# NUC400_v1 register map
File version: 1.0
Registers are 32-bit, read-write, reset 0x0 unless marked. A register's access mark holds for its fields unless they carry their own. Offsets are from the block's base; [hi:lo] are bit positions; {n}, {i} and the like mark numbered series.

## SYS — SYS Register Map
Base 0x40000000
0x00 SYS_PDID ro reset 0x140018 — Part Device Identification Number Register
  [31:0] PDID — Part Device Identification Number. This register reflects device part number code. S/W can read this register to identify which device is used.
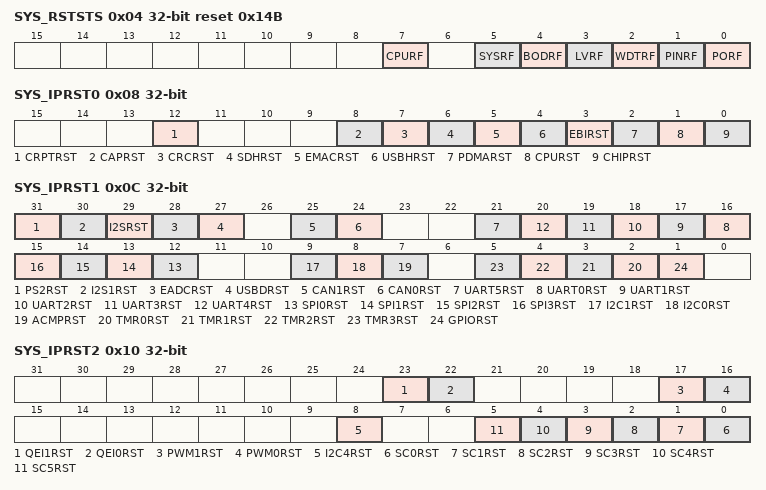
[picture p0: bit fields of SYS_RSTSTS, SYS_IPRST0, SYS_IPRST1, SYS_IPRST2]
0x04 SYS_RSTSTS reset 0x14B — System Reset Source Register
  [7] CPURF — CPU Reset Flag. The CPU reset flag is set by hardware if software writes CPURST (SYS_IPRST0[1]) 1 to reset Cortex-M4 Core and Flash Memory Controller (FMC). Note: Write to clear this bit to 0.
    0=No reset from CPU; 1=The Cortex-M4 Core and FMC are reset by software setting CPURST to 1
  [5] SYSRF — System Reset Flag. The system reset flag is set by the "Reset Signal" from the Cortex-M4 Core to indicate the previous reset source. Note: Write 1 to clear this bit to 0.
    0=No reset from Cortex-M4; 1=The Cortex-M4 had issued the reset signal to reset the system by writing 1 to the bit SYSRESETREQ(AIRCR[2], Application Interrupt and Reset Control Register, address = 0xE000ED0C) in system control registers of Cortex-M4 core
  [4] BODRF — BOD Reset Flag. The BOD reset flag is set by the "Reset Signal" from the Brown-Out Detector to indicate the previous reset source. Note: Write 1 to clear this bit to 0.
    0=No reset from BOD; 1=The BOD had issued the reset signal to reset the system
  [3] LVRF — LVR Reset Flag. The LVR reset flag is set by the "Reset Signal" from the Low Voltage Reset Controller to indicate the previous reset source. Note: Write 1 to clear this bit to 0.
    0=No reset from LVR; 1=LVR controller had issued the reset signal to reset the system
  [2] WDTRF — WDT Reset Flag. The WDT reset flag is set by the "Reset Signal" from the Watchdog Timer or Window Watchdog Timer to indicate the previous reset source. Note1: Write 1 to clear this bit to 0. Note2: Watchdog Timer register RSTF(WDT_CTL[2]) bit is set if the system has been reset by WDT time-out reset. Window Watchdog Timer register WWDTRF(WWDT_STATUS[1]) bit is set if the system has been reset by WWDT time-out reset.
    0=No reset from watchdog timer or window watchdog timer; 1=The watchdog timer or window watchdog timer had issued the reset signal to reset the system
  [1] PINRF — nRESET Pin Reset Flag. The nRESET pin reset flag is set by the "Reset Signal" from the nRESET Pin to indicate the previous reset source. Note: Write 1 to clear this bit to 0.
    0=No reset from nRESET pin; 1=Pin nRESET had issued the reset signal to reset the system
  [0] PORF — POR Reset Flag. The POR reset flag is set by the "Reset Signal" from the Power-on Reset (POR) Controller or bit CHIPRST (SYS_IPRST0[0]) to indicate the previous reset source. Note: Write 1 to clear this bit to 0.
    0=No reset from POR or CHIPRST; 1=Power-on Reset (POR) or CHIPRST had issued the reset signal to reset the system
0x08 SYS_IPRST0 — Peripheral Controller Reset Control Register 1
  [12] CRPTRST — CRYPTO Controller Reset (Write Protect). Setting this bit to 1 will generate a reset signal to the CRYPTO controller. User needs to set this bit to 0 to release from the reset state. This bit is a write protected bit, It means programming this bit needs to write "59h", "16h", "88h" to address 0x4000_0100 to disable register protection. Refer to the register SYS_REGLCTL at address GCR_BA+0x100
    0=CRYPTO controller normal operation; 1=CRYPTO controller reset
  [8] CAPRST — Image Capture Controller Reset (Write Protect). Setting this bit to 1 will generate a reset signal to the CAP controller. User needs to set this bit to 0 to release from the reset state. This bit is a write protected bit, It means programming this bit needs to write "59h", "16h", "88h" to address 0x4000_0100 to disable register protection. Reference the register SYS_REGLCTL at address GCR_BA+0x100
    0=CAP controller normal operation; 1=CAP controller reset
  [7] CRCRST — CRC Controller Reset (Write Protect). Setting this bit to 1 will generate a reset signal to the CRC controller. User needs to set this bit to 0 to release from the reset state. This bit is a write protected bit, It means programming this bit needs to write "59h", "16h", "88h" to address 0x4000_0100 to disable register protection. Reference the register SYS_REGLCTL at address GCR_BA+0x100
    0=CRC controller normal operation; 1=CRC controller reset
  [6] SDHRST — SD HOST Controller Reset (Write Protect). Setting this bit to 1 will generate a reset signal to the SD HOST controller. User needs to set this bit to 0 to release from the reset state. This bit is a write protected bit, It means programming this bit needs to write "59h", "16h", "88h" to address 0x4000_0100 to disable register protection. Refer to the register SYS_REGLCTL at address GCR_BA+0x100
    0=SD HOST controller normal operation; 1=SD HOST controller reset
  [5] EMACRST — EMAC Controller Reset (Write Protect). Setting this bit to 1 will generate a reset signal to the EMAC controller. User needs to set this bit to 0 to release from the reset state. This bit is the protected bit, It means programming this bit needs to write "59h", "16h", "88h" to address 0x4000_0100 to disable register protection. Refer to the register SYS_REGLCTL at address GCR_BA+0x100
    0=EMAC controller normal operation; 1=EMAC controller reset
  [4] USBHRST — USBH Controller Reset (Write Protect). Setting this bit to 1 will generate a reset signal to the HSB HOST controller. User needs to set this bit to 0 to release from the reset state. This bit is a write protected bit, It means programming this bit needs to write "59h", "16h", "88h" to address 0x4000_0100 to disable register protection. Refer to the register SYS_REGLCTL at address GCR_BA+0x100
    0=USBH controller normal operation; 1=USBH controller reset
  [3] EBIRST — EBI Controller Reset (Write Protect). Setting this bit to 1 will generate a reset signal to the EBI. User needs to set this bit to 0 to release from the reset state. This bit is a write protected bit, It means programming this bit needs to write "59h", "16h", "88h" to address 0x4000_0100 to disable register protection. Refer to the register SYS_REGLCTL at address GCR_BA+0x100
    0=EBI controller normal operation; 1=EBI controller reset
  [2] PDMARST — PDMA Controller Reset (Write Protect). Setting this bit to 1 will generate a reset signal to the PDMA. User needs to set this bit to 0 to release from reset state. This bit is a write protected bit, It means programming this bit needs to write "59h", "16h", "88h" to address 0x4000_0100 to disable register protection. Refer to the register SYS_REGLCTL at address GCR_BA+0x100.
    0=PDMA controller normal operation; 1=PDMA controller reset
  [1] CPURST — Processor Core One-Shot Reset (Write Protect). Setting this bit will only reset the processor core and Flash Memory Controller(FMC), and this bit will automatically return to 0 after the 2 clock cycles. This bit is a write protected bit, It means programming this bit needs to write "59h", "16h", "88h" to address 0x4000_0100 to disable register protection. Refer to the register SYS_REGLCTL at address GCR_BA+0x100
    0=Processor core normal operation; 1=Processor core one-shot reset
  [0] CHIPRST — Chip One-Shot Reset (Write Protect). Setting this bit will reset the whole chip, including Processor core and all peripherals, and this bit will automatically return to 0 after the 2 clock cycles. The CHIPRST is same as the POR reset, all the chip controllers is reset and the chip setting from flash are also reload. This bit is a write protected bit, which means programming this bit needs to write "59h", "16h", "88h" to address 0x4000_0100 to disable register protection. Refer to the register SYS_REGLCTL at address GCR_BA+0x100
    0=Chip normal operation; 1=Chip one shot reset
0x0C SYS_IPRST1 — Peripheral Controller Reset Control Register 2
  [31] PS2RST — PS/2 Controller Reset
    0=PS/2 controller normal operation; 1=PS/2 controller reset
  [30] I2S1RST — I2S1 Controller Reset
    0=I2S1 controller normal operation; 1=I2S1 controller reset
  [29] I2SRST — I2S Controller Reset
    0=I2S controller normal operation; 1=I2S controller reset
  [28] EADCRST — ADC Controller Reset
    0=ADC controller normal operation; 1=ADC controller reset
  [27] USBDRST — USB Device Controller Reset
    0=USB device controller normal operation; 1=USB device controller reset
  [25] CAN1RST — CAN1 Controller Reset
    0=CAN1 controller normal operation; 1=CAN1 controller reset
  [24] CAN0RST — CAN0 Controller Reset
    0=CAN0 controller normal operation; 1=CAN0 controller reset
  [21] UART5RST — UART2 Controller Reset
    0=UART5 controller normal operation; 1=UART5 controller reset
  [n+16] UART{n}RST (n=0..4) — UART{n} Controller Reset
    0=UART{n} controller normal operation; 1=UART{n} controller reset
  [n+12] SPI{n}RST (n=0..3) — SPI{n} Controller Reset
    0=SPI{n} controller normal operation; 1=SPI{n} controller reset
  [9] I2C1RST — I2C1 Controller Reset
    0=I2C1 controller normal operation; 1=I2C1 controller reset
  [8] I2C0RST — I2C0 Controller Reset
    0=I2C0 controller normal operation; 1=I2C0 controller reset
  [7] ACMPRST — Analog Comparator Controller Reset
    0=Analog Comparator controller normal operation; 1=Analog Comparator controller reset
  [n+2] TMR{n}RST (n=0..3) — Timer{n} Controller Reset
    0=Timer{n} controller normal operation; 1=Timer{n} controller reset
  [1] GPIORST — GPIO Controller Reset
    0=GPIO controller normal operation; 1=GPIO controller reset
0x10 SYS_IPRST2 — Peripheral Controller Reset Control Register 3
  [23] QEI1RST — QEI1 Controller Reset
    0=QEI1 controller normal operation; 1=QEI1 controller reset
  [22] QEI0RST — QEI0 Controller Reset
    0=QEI0 controller normal operation; 1=QEI0 controller reset
  [17] PWM1RST — PWM1 Controller Reset
    0=PWM1 controller normal operation; 1=PWM1 controller reset
  [16] PWM0RST — PWM0 Controller Reset
    0=PWM0 controller normal operation; 1=PWM0 controller reset
  [8] I2C4RST — I2C4 Controller Reset
    0=I2C4 controller normal operation; 1=I2C4 controller reset
  [n] SC{n}RST (n=0..5) — SC{n} Controller Reset
    0=SC{n} controller normal operation; 1=SC{n} controller reset
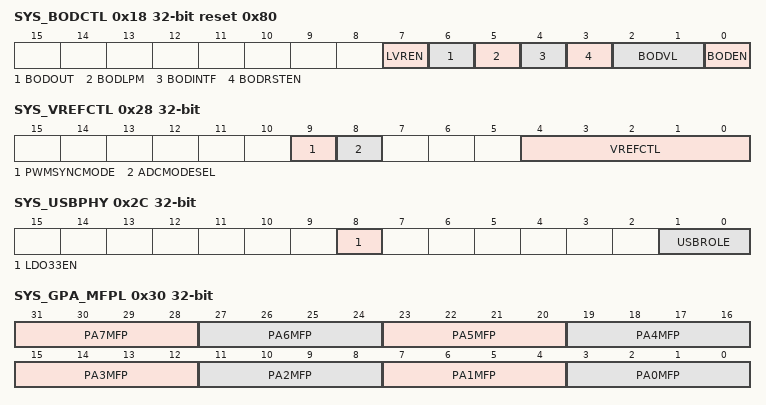
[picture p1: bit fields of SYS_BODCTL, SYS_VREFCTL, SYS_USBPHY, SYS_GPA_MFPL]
0x18 SYS_BODCTL reset 0x80 (reset mask 0xFFFFFFF0) — Brown-out Detector Control Register
  [7] LVREN — Low Voltage Reset Enable Bit (Write Protect). The LVR function reset the chip when the input power voltage is lower than LVR circuit setting. LVR function is enabled in default. This bit is the protected bit, which means programming this needs to write "59h", "16h", "88h" to address 0x4000_0100 to disable register protection. Refer to the register SYS_REGLCTL at address GCR_BA+0x100
    0=Low Voltage Reset function Disabled; 1=Low Voltage Reset function Enabled - After enabling the bit, the LVR function will be active with 100uS delay for LVR output stable (default)
  [6] BODOUT — Brown-Out Detector Output Status
    0=Brown-out Detector output status is 0. It means the detected voltage is higher than BODVL setting or BODEN is 0; 1=Brown-out Detector output status is 1. It means the detected voltage is lower than BODVL setting. If the BODEN is 0, BOD function disabled , this bit always responds 0000
  [5] BODLPM — Brown-Out Detector Low Power Mode (Write Protect). The BOD consumes about 100uA in normal mode, the low power mode can reduce the current to about 1/10 but slow the BOD response. This bit is the protected bit, which means programming this needs to write "59h", "16h", "88h" to address 0x4000_0100 to disable register protection. Refer to the register SYS_REGLCTL at address GCR_BA+0x100.
    0=BOD operate in normal mode (default); 1=BOD Low Power mode Enabled
  [4] BODINTF — Brown-Out Detector Interrupt Flag. Note: Write 1 to clear this bit to 0.
    0=Brown-out Detector does not detect any voltage draft at VDD down through or up through the voltage of BODVL setting; 1=When Brown-out Detector detects the VDD is dropped down through the voltage of BODVL setting or the VDD is raised up through the voltage of BODVL setting, this bit is set to 1 and the brown-out interrupt is requested if brown-out interrupt is enabled
  [3] BODRSTEN — Brown-Out Reset Enable Bit (Write Protect). While the Brown-out Detector function is enabled (BODEN high) and BOD reset function is enabled (BODRSTEN high), BOD will assert a signal to reset chip when the detected voltage is lower than the threshold (BODOUT high). While the BOD function is enabled (BODEN high) and BOD interrupt function is enabled (BODRSTEN low), BOD will assert an interrupt if BODOUT is high. BOD interrupt will keep till to the BODEN set to 0. BOD interrupt can be blocked by disabling the NVIC BOD interrupt or disabling BOD function (set BODEN low). The default value is set by flash controller user configuration register config0 bit[20]. This bit is the protected bit, which means programming this needs to write "59h", "16h", "88h" to address 0x4000_0100 to disable register protection. Refer to the register SYS_REGLCTL at address GCR_BA+0x100.
    0=Brown-out "INTERRUPT" function Enabled; 1=Brown-out "RESET" function Enabled
  [2:1] BODVL — Brown-Out Detector Threshold Voltage Selection (Write Protect). The default value is set by flash controller user configuration register config0 bit[22:21]. Relationship between BODVL and Brown-out voltage listed below: This bit is the protected bit, which means programming this needs to write "59h", "16h", "88h" to address 0x4000_0100 to disable register protection. Refer to the register SYS_REGLCTL at address GCR_BA+0x100.
    0=2.2V; 1=2.7V; 2=3.7V; 3=4.5V
  [0] BODEN — Brown-Out Detector Enable Bit (Write Protect). The default value is set by flash controller user configuration register config0 bit[23]. This bit is the protected bit, which means programming this needs to write "59h", "16h", "88h" to address 0x4000_0100 to disable register protection. Refer to the register SYS_REGLCTL at address GCR_BA+0x100.
    0=Brown-out Detector function Disabled; 1=Brown-out Detector function Enabled
0x1C SYS_TEMPCTL — Temperature Sensor Control Register
  [0] VTEMPEN — Temperature Sensor Enable Bit. This bit is used to enable/disable temperature sensor function. After this bit is set to 1, the value of temperature sensor output can be obtained from ADC conversion result. Please refer to ADC function chapter for details.
    0=Temperature sensor function Disabled (default); 1=Temperature sensor function Enabled
0x20 SYS_VCID ro — Hardware Version Control Register
  [15:0] VCID — Hardware Version Control (Ready Only). These registers repress hardware version. These bits are the read protected bits. It means programming this needs to write "59h", "16h", "88h" to address 0x4000_0100 to disable register protection. Refer to the register SYS_REGLCTL at address GCR_BA+0x100.
0x24 SYS_PORCTL — Power-On-reset Controller Register
  [15:0] POROFF — Power-On-Reset Enable Bit (Write Protect). When power on, the POR circuit generates a reset signal to reset the whole chip function, but noise on the power may cause the POR active again. User can disable internal POR circuit to avoid unpredictable noise to cause chip reset by writing 0x5AA5 to this field. The POR function will be active again when this field is set to another value or chip is reset by other reset source, including: /RESET, Watch dog, LVR reset, BOD reset, ICE reset command and the software-chip reset function. This bit is the protected bit, which means programming this needs to write "59h", "16h", "88h" to address 0x4000_0100 to disable register protection. Refer to the register SYS_REGLCTL at address GCR_BA+0x100.
0x28 SYS_VREFCTL — ADC VREF Control Register
  [9] PWMSYNCMODE — PWM SYNC MODE (Write Protect)
    0=PWM SYNC MODE Disabled; PWM engine clock can different with HCLK; 1=PWM SYNC MODE Enabled; PWM engine clock is same as HCLK
  [8] ADCMODESEL — ADC IP Selection (Write Protect)
    0=ADC mode; 1=E ADC mode
  [4:0] VREFCTL — VREF Control Bits (Write Protect)
    3=VREF is internal 2.65V; 7=VREF is internal 2.048V; 11=VREF is internal 3.072V; 15=VREF is internal 4.096V; 16=VREF is from AVDD
0x2C SYS_USBPHY (reset mask 0xFFFFFFF0) — USB PHY Control Register
  [8] LDO33EN — LDO33 Enable Bit (Write Protect)
    0=USB LDO33 Disabled; 1=USB LDO33 Enabled
  [1:0] USBROLE — USB Role Configuration (Write Protect). USB role configuration can be from ROMMAP or software setting if software setting option, controlled by ROMMAP, is enabled.
    0=Standard USB device; 1=Standard USB host; 2=ID dependent device; 3=On-The-Go device
0x30 SYS_GPA_MFPL — Port A Low Byte Multi-function Control Register
  [31:28] PA7MFP — PA.7 Multi-function Pin Selection
  [27:24] PA6MFP — PA.6 Multi-function Pin Selection
  [23:20] PA5MFP — PA.5 Multi-function Pin Selection
  [19:16] PA4MFP — PA.4 Multi-function Pin Selection
  [15:12] PA3MFP — PA.3 Multi-function Pin Selection
  [11:8] PA2MFP — PA.2 Multi-function Pin Selection
  [7:4] PA1MFP — PA.1 Multi-function Pin Selection
  [3:0] PA0MFP — PA.0 Multi-function Pin Selection
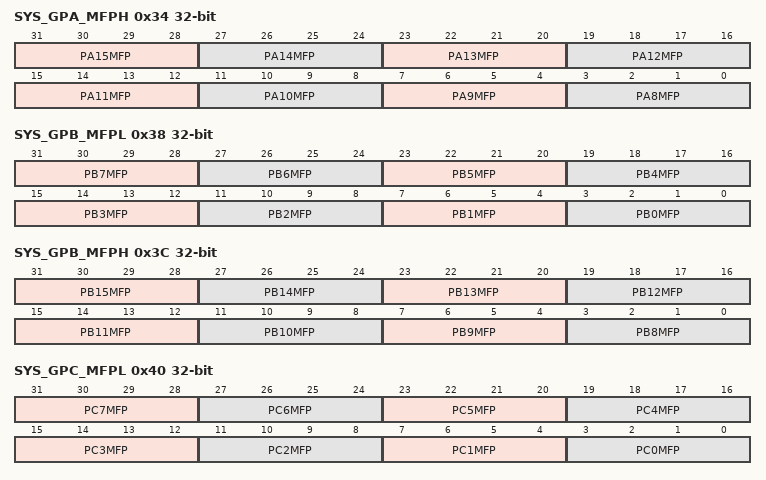
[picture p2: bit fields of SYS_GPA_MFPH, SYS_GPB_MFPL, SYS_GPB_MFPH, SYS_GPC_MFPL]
0x34 SYS_GPA_MFPH — Port A High Byte Multi-function Control Register
  [31:28] PA15MFP — PA.15 Multi-function Pin Selection
  [27:24] PA14MFP — PA.14 Multi-function Pin Selection
  [23:20] PA13MFP — PA.13 Multi-function Pin Selection
  [19:16] PA12MFP — PA.12 Multi-function Pin Selection
  [15:12] PA11MFP — PA.11 Multi-function Pin Selection
  [11:8] PA10MFP — PA.10 Multi-function Pin Selection
  [7:4] PA9MFP — PA.9 Multi-function Pin Selection
  [3:0] PA8MFP — PA.8 Multi-function Pin Selection
0x38 SYS_GPB_MFPL — Port B Low Byte Multi-function Control Register
  [31:28] PB7MFP — PB.7 Multi-function Pin Selection
  [27:24] PB6MFP — PB.6 Multi-function Pin Selection
  [23:20] PB5MFP — PB.5 Multi-function Pin Selection
  [19:16] PB4MFP — PB.4 Multi-function Pin Selection
  [15:12] PB3MFP — PB.3 Multi-function Pin Selection
  [11:8] PB2MFP — PB.2 Multi-function Pin Selection
  [7:4] PB1MFP — PB.1 Multi-function Pin Selection
  [3:0] PB0MFP — PB.0 Multi-function Pin Selection
0x3C SYS_GPB_MFPH — Port B High Byte Multi-function Control Register
  [31:28] PB15MFP — PB.15 Multi-function Pin Selection
  [27:24] PB14MFP — PB.14 Multi-function Pin Selection
  [23:20] PB13MFP — PB.13 Multi-function Pin Selection
  [19:16] PB12MFP — PB.12 Multi-function Pin Selection
  [15:12] PB11MFP — PB.11 Multi-function Pin Selection
  [11:8] PB10MFP — PB.10 Multi-function Pin Selection
  [7:4] PB9MFP — PB.9 Multi-function Pin Selection
  [3:0] PB8MFP — PB.8 Multi-function Pin Selection
0x40 SYS_GPC_MFPL — Port C Low Byte Multi-function Control Register
  [31:28] PC7MFP — PC.7 Multi-function Pin Selection
  [27:24] PC6MFP — PC.6 Multi-function Pin Selection
  [23:20] PC5MFP — PC.5 Multi-function Pin Selection
  [19:16] PC4MFP — PC.4 Multi-function Pin Selection
  [15:12] PC3MFP — PC.3 Multi-function Pin Selection
  [11:8] PC2MFP — PC.2 Multi-function Pin Selection
  [7:4] PC1MFP — PC.1 Multi-function Pin Selection
  [3:0] PC0MFP — PC.0 Multi-function Pin Selection
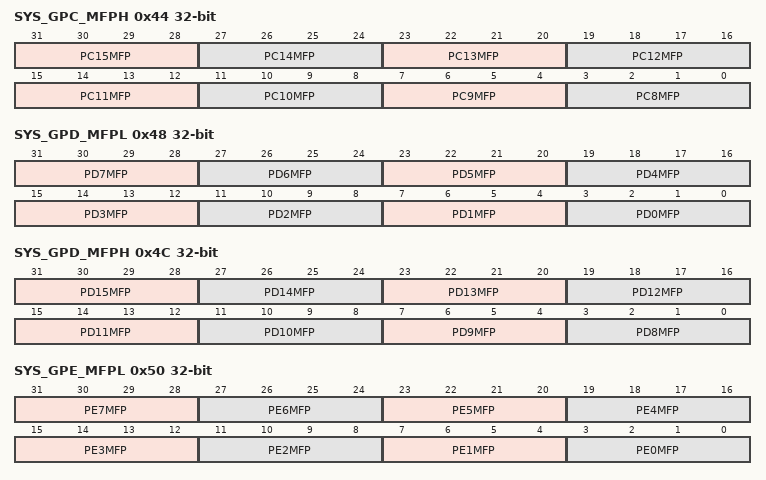
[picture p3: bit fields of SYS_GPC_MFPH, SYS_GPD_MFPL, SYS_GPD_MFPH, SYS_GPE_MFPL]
0x44 SYS_GPC_MFPH — Port C High Byte Multi-function Control Register
  [31:28] PC15MFP — PC.15 Multi-function Pin Selection
  [27:24] PC14MFP — PC.14 Multi-function Pin Selection
  [23:20] PC13MFP — PC.13 Multi-function Pin Selection
  [19:16] PC12MFP — PC.12 Multi-function Pin Selection
  [15:12] PC11MFP — PC.11 Multi-function Pin Selection
  [11:8] PC10MFP — PC.10 Multi-function Pin Selection
  [7:4] PC9MFP — PC.9 Multi-function Pin Selection
  [3:0] PC8MFP — PC.8 Multi-function Pin Selection
0x48 SYS_GPD_MFPL — Port D Low Byte Multi-function Control Register
  [31:28] PD7MFP — PD.7 Multi-function Pin Selection
  [27:24] PD6MFP — PD.6 Multi-function Pin Selection
  [23:20] PD5MFP — PD.5 Multi-function Pin Selection
  [19:16] PD4MFP — PD.4 Multi-function Pin Selection
  [15:12] PD3MFP — PD.3 Multi-function Pin Selection
  [11:8] PD2MFP — PD.2 Multi-function Pin Selection
  [7:4] PD1MFP — PD.1 Multi-function Pin Selection
  [3:0] PD0MFP — PD.0 Multi-function Pin Selection
0x4C SYS_GPD_MFPH — Port D High Byte Multi-function Control Register
  [31:28] PD15MFP — PD.15 Multi-function Pin Selection
  [27:24] PD14MFP — PD.14 Multi-function Pin Selection
  [23:20] PD13MFP — PD.13 Multi-function Pin Selection
  [19:16] PD12MFP — PD.12 Multi-function Pin Selection
  [15:12] PD11MFP — PD.11 Multi-function Pin Selection
  [11:8] PD10MFP — PD.10 Multi-function Pin Selection
  [7:4] PD9MFP — PD.9 Multi-function Pin Selection
  [3:0] PD8MFP — PD.8 Multi-function Pin Selection
0x50 SYS_GPE_MFPL — Port E Low Byte Multi-function Control Register
  [31:28] PE7MFP — PE.7 Multi-function Pin Selection
  [27:24] PE6MFP — PE.6 Multi-function Pin Selection
  [23:20] PE5MFP — PE.5 Multi-function Pin Selection
  [19:16] PE4MFP — PE.4 Multi-function Pin Selection
  [15:12] PE3MFP — PE.3 Multi-function Pin Selection
  [11:8] PE2MFP — PE.2 Multi-function Pin Selection
  [7:4] PE1MFP — PE.1 Multi-function Pin Selection
  [3:0] PE0MFP — PE.0 Multi-function Pin Selection
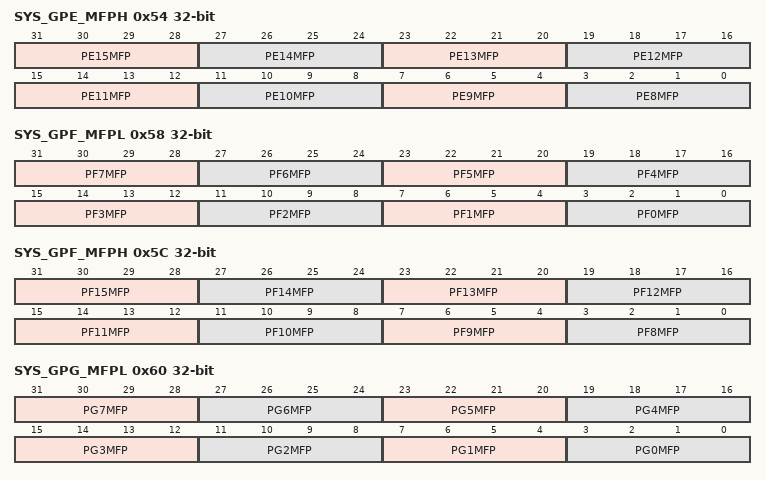
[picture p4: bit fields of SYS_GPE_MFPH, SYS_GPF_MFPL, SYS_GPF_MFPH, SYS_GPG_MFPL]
0x54 SYS_GPE_MFPH — Port E High Byte Multi-function Control Register
  [31:28] PE15MFP — PE.15 Multi-function Pin Selection
  [27:24] PE14MFP — PE.14 Multi-function Pin Selection
  [23:20] PE13MFP — PE.13 Multi-function Pin Selection
  [19:16] PE12MFP — PE.12 Multi-function Pin Selection
  [15:12] PE11MFP — PE.11 Multi-function Pin Selection
  [11:8] PE10MFP — PE.10 Multi-function Pin Selection
  [7:4] PE9MFP — PE.9 Multi-function Pin Selection
  [3:0] PE8MFP — PE.8 Multi-function Pin Selection
0x58 SYS_GPF_MFPL — Port F Low Byte Multi-function Control Register
  [31:28] PF7MFP — PF.7 Multi-function Pin Selection
  [27:24] PF6MFP — PF.6 Multi-function Pin Selection
  [23:20] PF5MFP — PF.5 Multi-function Pin Selection
  [19:16] PF4MFP — PF.4 Multi-function Pin Selection
  [15:12] PF3MFP — PF.3 Multi-function Pin Selection
  [11:8] PF2MFP — PF.2 Multi-function Pin Selection
  [7:4] PF1MFP — PF.1 Multi-function Pin Selection
  [3:0] PF0MFP — PF.0 Multi-function Pin Selection
0x5C SYS_GPF_MFPH — Port F High Byte Multi-function Control Register
  [31:28] PF15MFP — PF.15 Multi-function Pin Selection
  [27:24] PF14MFP — PF.14 Multi-function Pin Selection
  [23:20] PF13MFP — PF.13 Multi-function Pin Selection
  [19:16] PF12MFP — PF.12 Multi-function Pin Selection
  [15:12] PF11MFP — PF.11 Multi-function Pin Selection
  [11:8] PF10MFP — PF.10 Multi-function Pin Selection
  [7:4] PF9MFP — PF.9 Multi-function Pin Selection
  [3:0] PF8MFP — PF.8 Multi-function Pin Selection
0x60 SYS_GPG_MFPL — Port G Low Byte Multi-function Control Register
  [31:28] PG7MFP — PG.7 Multi-function Pin Selection
  [27:24] PG6MFP — PG.6 Multi-function Pin Selection
  [23:20] PG5MFP — PG.5 Multi-function Pin Selection
  [19:16] PG4MFP — PG.4 Multi-function Pin Selection
  [15:12] PG3MFP — PG.3 Multi-function Pin Selection
  [11:8] PG2MFP — PG.2 Multi-function Pin Selection
  [7:4] PG1MFP — PG.1 Multi-function Pin Selection
  [3:0] PG0MFP — PG.0 Multi-function Pin Selection
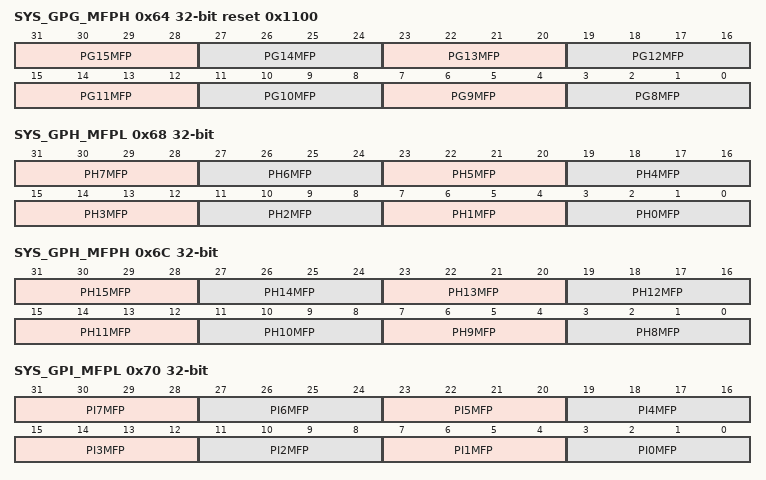
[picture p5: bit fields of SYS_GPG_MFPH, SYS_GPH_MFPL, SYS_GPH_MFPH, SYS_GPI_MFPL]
0x64 SYS_GPG_MFPH reset 0x1100 (reset mask 0xFFFF) — Port G High Byte Multi-function Control Register
  [31:28] PG15MFP — PG.15 Multi-function Pin Selection
  [27:24] PG14MFP — PG.14 Multi-function Pin Selection
  [23:20] PG13MFP — PG.13 Multi-function Pin Selection
  [19:16] PG12MFP — PG.12 Multi-function Pin Selection
  [15:12] PG11MFP — PG.11 Multi-function Pin Selection
  [11:8] PG10MFP — PG.10 Multi-function Pin Selection
  [7:4] PG9MFP — PG.9 Multi-function Pin Selection
  [3:0] PG8MFP — PG.8 Multi-function Pin Selection
0x68 SYS_GPH_MFPL — Port H Low Byte Multi-function Control Register
  [31:28] PH7MFP — PH.7 Multi-function Pin Selection
  [27:24] PH6MFP — PH.6 Multi-function Pin Selection
  [23:20] PH5MFP — PH.5 Multi-function Pin Selection
  [19:16] PH4MFP — PH.4 Multi-function Pin Selection
  [15:12] PH3MFP — PH.3 Multi-function Pin Selection
  [11:8] PH2MFP — PH.2 Multi-function Pin Selection
  [7:4] PH1MFP — PH.1 Multi-function Pin Selection
  [3:0] PH0MFP — PH.0 Multi-function Pin Selection
0x6C SYS_GPH_MFPH — Port H High Byte Multi-function Control Register
  [31:28] PH15MFP — PH.15 Multi-function Pin Selection
  [27:24] PH14MFP — PH.14 Multi-function Pin Selection
  [23:20] PH13MFP — PH.13 Multi-function Pin Selection
  [19:16] PH12MFP — PH.12 Multi-function Pin Selection
  [15:12] PH11MFP — PH.11 Multi-function Pin Selection
  [11:8] PH10MFP — PH.10 Multi-function Pin Selection
  [7:4] PH9MFP — PH.9 Multi-function Pin Selection
  [3:0] PH8MFP — PH.8 Multi-function Pin Selection
0x70 SYS_GPI_MFPL — Port I Low Byte Multi-function Control Register
  [31:28] PI7MFP — PI.7 Multi-function Pin Selection
  [27:24] PI6MFP — PI.6 Multi-function Pin Selection
  [23:20] PI5MFP — PI.5 Multi-function Pin Selection
  [19:16] PI4MFP — PI.4 Multi-function Pin Selection
  [15:12] PI3MFP — PI.3 Multi-function Pin Selection
  [11:8] PI2MFP — PI.2 Multi-function Pin Selection
  [7:4] PI1MFP — PI.1 Multi-function Pin Selection
  [3:0] PI0MFP — PI.0 Multi-function Pin Selection
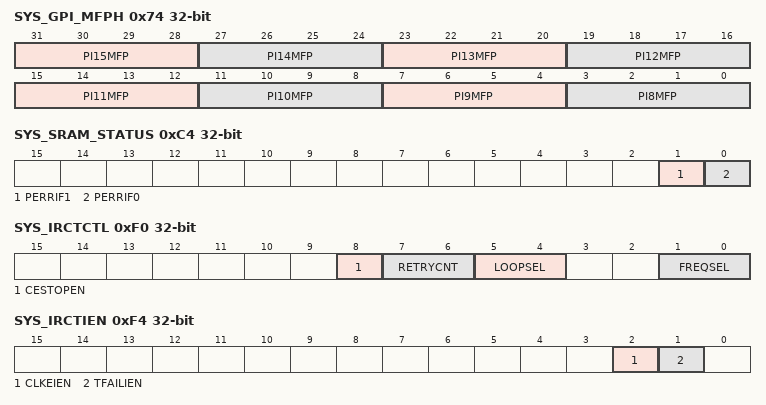
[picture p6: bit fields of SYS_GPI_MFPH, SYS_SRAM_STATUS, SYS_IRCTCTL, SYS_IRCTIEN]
0x74 SYS_GPI_MFPH — Port I High Byte Multi-function Control Register
  [31:28] PI15MFP — PI.15 Multi-function Pin Selection
  [27:24] PI14MFP — PI.14 Multi-function Pin Selection
  [23:20] PI13MFP — PI.13 Multi-function Pin Selection
  [19:16] PI12MFP — PI.12 Multi-function Pin Selection
  [15:12] PI11MFP — PI.11 Multi-function Pin Selection
  [11:8] PI10MFP — PI.10 Multi-function Pin Selection
  [7:4] PI9MFP — PI.9 Multi-function Pin Selection
  [3:0] PI8MFP — PI.8 Multi-function Pin Selection
0xC0 SYS_SRAM_INTCTL — SRAM Failed Interrupt Enable Control Register
  [0] PERRIEN — SRAM Parity Check Fail Interrupt Enable Bit
    0=SRAMF INT Disabled; 1=SRAMF INT Enabled when SRAM fail flag
0xC4 SYS_SRAM_STATUS — SRAM Parity Check Error Flag
  [1] PERRIF1 — SRAM Parity Check Fail Flag
    0=2nd SRAM fail; 1=2nd SRAM Fail
  [0] PERRIF0 — SRAM Parity Check Fail Flag
    0=No first 1 SRAM fail; 1=First SRAM Fail
0xC8 SYS_SRAM0_ERRADDR ro — SRAM Parity Check Error First Address1
  [31:0] PERRADDR — First SRAM Parity Check Fail Address. This register shows the first system SRAM parity error byte address.
0xCC SYS_SRAM1_ERRADDR ro — SRAM Parity Check Error First Address2
  [31:0] PERRADDR — Second SRAM Parity Check Fail Address. This register shows the second system SRAM parity error byte address.
0xF0 SYS_IRCTCTL — IRC Trim Control Register
  [8] CESTOPEN — Clock Error Stop Enable Bit
    0=The trim operation is keep going if clock is inaccuracy; 1=The trim operation is stopped if clock is inaccuracy
  [7:6] RETRYCNT — Trim Value Update Limitation Count. This field defines that how many times the auto trim circuit will try to update the HIRC trim value before the frequency of HIRC locked. Once the HIRC locked, the internal trim value update counter will be reset. If the trim value update counter reached this limitation value and frequency of HIRC still doesn't lock, the auto trim operation will be disabled and FREQSEL will be cleared to 00.
    0=Trim retry count limitation is 64; 1=Trim retry count limitation is 128; 2=Trim retry count limitation is 256; 3=Trim retry count limitation is 512
  [5:4] LOOPSEL — Trim Calculation Loop. This field defines that trim value calculation is based on how many 32.768 kHz clock. For example, if CALCLOOP is set as 00, auto trim circuit will calculate trim value based on the average frequency difference in 4 32.768 kHz clock.
    0=Trim value calculation is based on average difference in 4 32.768 kHz clock; 1=Trim value calculation is based on average difference in 8 32.768 kHz clock; 2=Trim value calculation is based on average difference in 16 32.768 kHz clock; 3=Trim value calculation is based on average difference in 32 32.768 kHz clock
  [1:0] FREQSEL — Trim Frequency Selection. This field indicates the target frequency of HIRC auto trim. If no any target frequency is selected (FREQSEL is 00), the HIRC auto trim function is disabled. During auto trim operation, if clock error detected with CESTOPEN is set to 1 or trim retry limitation count reached, this field will be cleared to 00 automatically.
    0=Disable HIRC auto trim function; 1=Enable HIRC auto trim function and trim HIRC to 22.1184 MHz; 2=Enable HIRC auto trim function and trim HIRC to 24 MHz
0xF4 SYS_IRCTIEN — IRC Trim Interrupt Enable Control Register
  [2] CLKEIEN — Clock Error Interrupt Enable Bit. This bit controls if CPU would get an interrupt while clock is inaccuracy during auto trim operation. If this bit is set to1, and CLKERRIF is set during auto trim operation, an interrupt will be triggered to notify the clock frequency is inaccuracy.
    0=Disable CLKERRIF status to trigger an interrupt to CPU; 1=Enable CLKERRIF status to trigger an interrupt to CPU
  [1] TFAILIEN — Trim Failure Interrupt Enable. This bit controls if an interrupt will be triggered while HIRC trim value update limitation count reached and HIRC frequency still not locked on target frequency set by FREQSEL. If this bit is high and TFAILIF is set during auto trim operation, an interrupt will be triggered to notify that HIRC trim value update limitation count was reached.
    0=Disable TFAILIF status to trigger an interrupt to CPU; 1=Enable TFAILIF status to trigger an interrupt to CPU
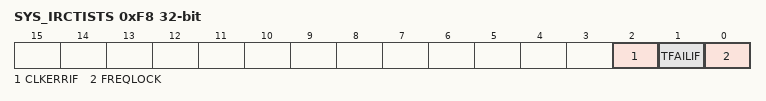
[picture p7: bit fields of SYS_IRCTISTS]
0xF8 SYS_IRCTISTS — IRC Trim Interrupt Status Register
  [2] CLKERRIF — Clock Error Interrupt Status. When the frequency of external 32.768 kHz low-speed crystal or HIRC is shift larger to unreasonable value, this bit will be set and to be an indicate that clock frequency is inaccuracy. Once this bit is set to 1, the auto trim operation stopped and FREQSEL will be cleared to 00 by hardware automatically if CESTOPEN is set to 1. If this bit is set and CLKEIEN is high, an interrupt will be triggered to notify the clock frequency is inaccuracy. Write 1 to clear this to 0.
    0=Clock frequency is accuracy; 1=Clock frequency is inaccuracy
  [1] TFAILIF — Trim Failure Interrupt Status. This bit indicates that HIRC trim value update limitation count reached and the HIRC clock frequency still doesn't be locked. Once this bit is set, the auto trim operation stopped and FREQSEL will be cleared to 00 by hardware automatically. If this bit is set and TFAILIEN is high, an interrupt will be triggered to notify that HIRC trim value update limitation count was reached. Write 1 to clear this to 0.
    0=Trim value update limitation count does not reach; 1=Trim value update limitation count reached and HIRC frequency still not locked
  [0] FREQLOCK — HIRC Frequency Lock Status. This bit indicates the HIRC frequency is locked. This is a status bit and doesn't trigger any interrupt.
0x100 SYS_REGLCTL — Register Write-protection Control Register
  [7:0] REGLCTL — Register Write-Protection Code (Write Only). Some registers have write-protection function. Writing these registers have to disable the protected function by writing the sequence value "59h", "16h", "88h" to this field. After this sequence is completed, the REGLCTL bit will be set to 1 and write-protection registers can be normal write. Register Write-Protection Disable Index (Read Only). The Protected registers are: SYS_IPRST0: address 0x4000_0008. SYS_BODCTL: address 0x4000_0018. SYS_PORCTL: address 0x4000_0024. PWRCTL: address 0x4000_0200 (bit[6] is not protected for power wake-up interrupt clear). APBCLK bit[0]: address 0x4000_0208 (bit[0] is watchdog clock enable). CLKSEL0: address 0x4000_0210 (for HCLK and CPU STCLK clock source select). CLKSEL1 bit[1:0]: address 0x4000_0214 (for watchdog clock source select). NMI_SEL]: address 0x4000_0300 (for NMI source select). ISPCON: address 0x4000_5000 (Flash ISP Control register). ISPTRG: address 0x4000_5010 (ISP Trigger Control register). WTCR: address 0x4004_0000. FATCON: address 0x4000_5018. TAMPER: address 0x400E_1000
    0=Write-protection Enabled for writing protected registers. Any write to the protected register is ignored; 1=Write-protection Disabled for writing protected registers
